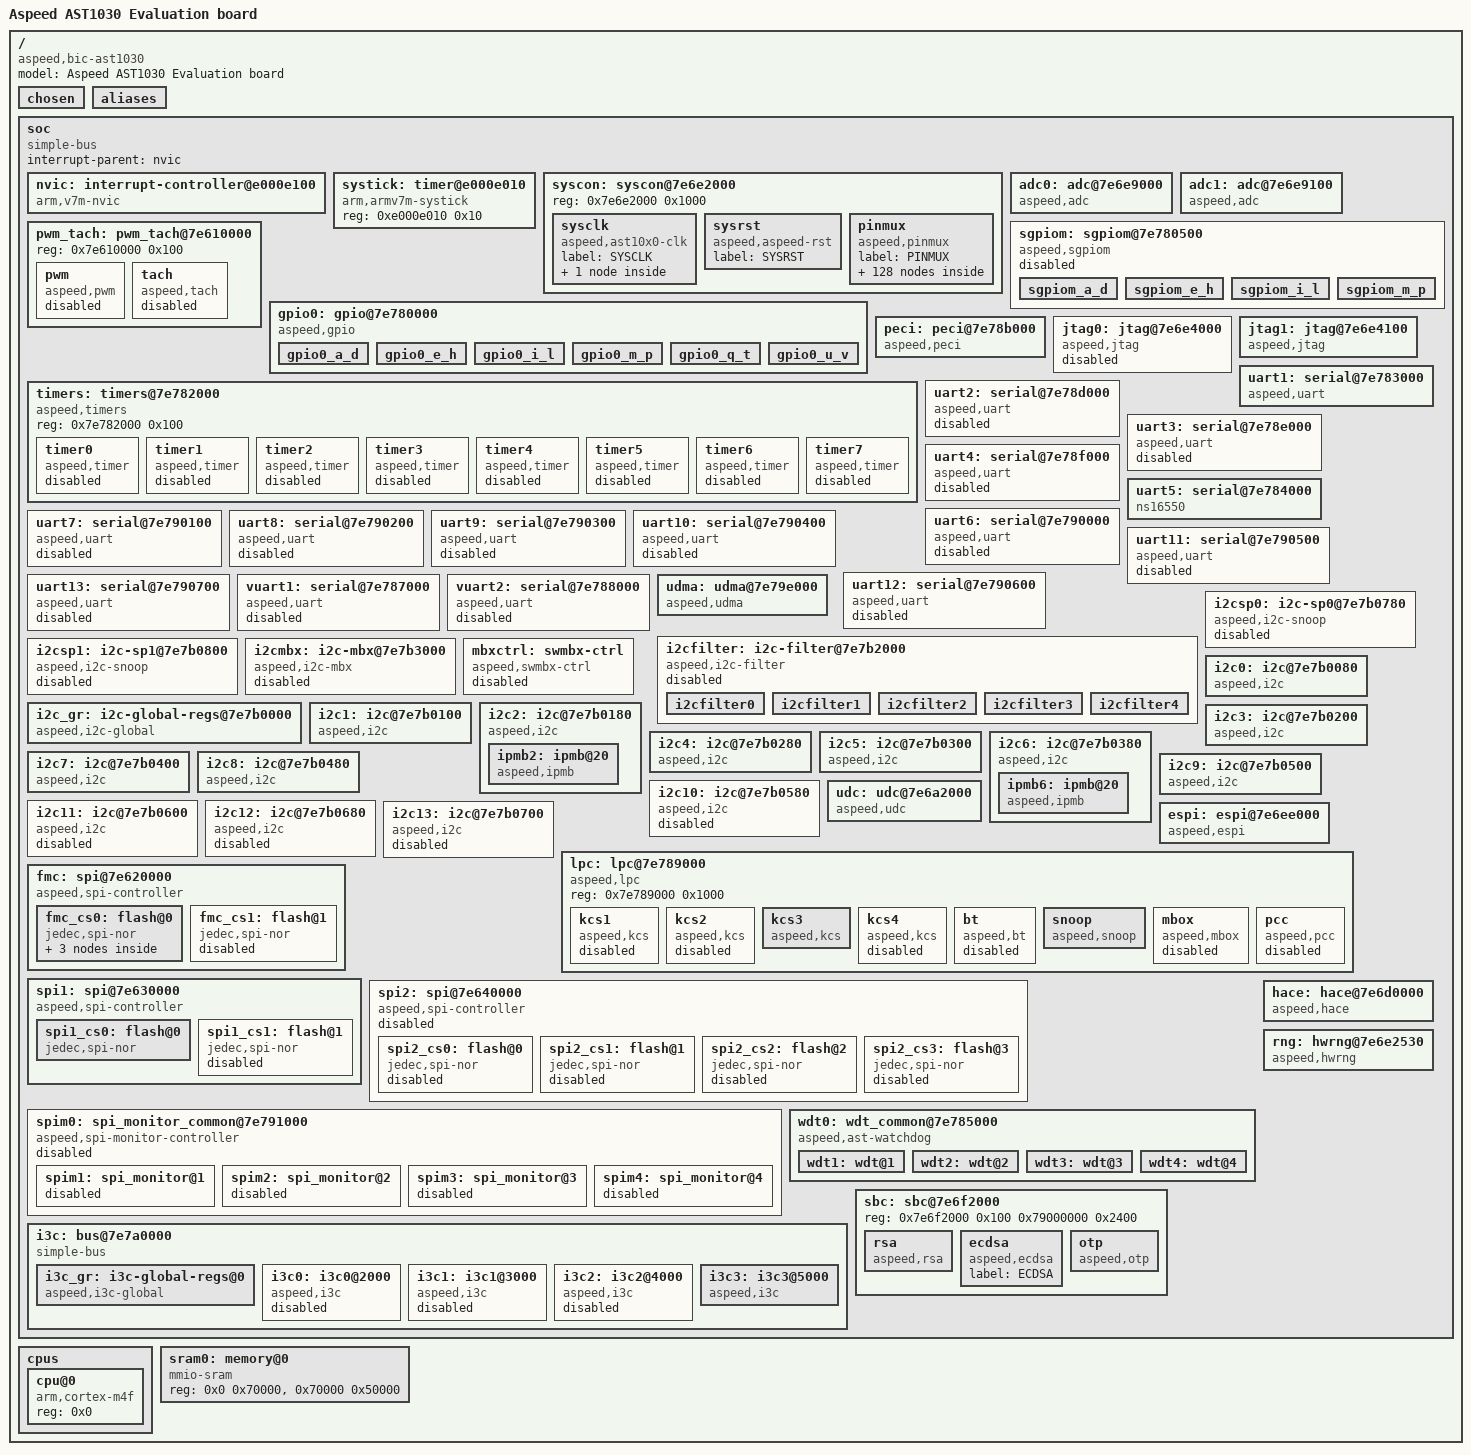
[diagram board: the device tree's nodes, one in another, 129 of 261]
/dts-v1/;

/ {
	#address-cells = < 0x1 >;
	#size-cells = < 0x1 >;
	model = "Aspeed AST1030 Evaluation board";
	compatible = "aspeed,bic-ast1030", "aspeed,ast1030";
	chosen {
		zephyr,console = &uart5;
		zephyr,shell-uart = &uart5;
		zephyr,sram = &sram0;
		zephyr,flash = &fmc_cs0;
		zephyr,entropy = &rng;
	};
	aliases {
	};
	soc {
		#address-cells = < 0x1 >;
		#size-cells = < 0x1 >;
		compatible = "simple-bus";
		interrupt-parent = < &nvic >;
		ranges;
		nvic: interrupt-controller@e000e100 {
			compatible = "arm,v7m-nvic";
			reg = < 0xe000e100 0xc00 >;
			interrupt-controller;
			#interrupt-cells = < 0x2 >;
			arm,num-irq-priority-bits = < 0x3 >;
			phandle = < 0x1 >;
		};
		systick: timer@e000e010 {
			compatible = "arm,armv7m-systick";
			reg = < 0xe000e010 0x10 >;
		};
		syscon: syscon@7e6e2000 {
			reg = < 0x7e6e2000 0x1000 >;
			phandle = < 0x5 >;
			sysclk: sysclk {
				compatible = "aspeed,ast10x0-clk";
				#clock-cells = < 0x1 >;
				label = "SYSCLK";
				phandle = < 0x2 >;
				adc_clk: adc_clk {
					#clock-cells = < 0x0 >;
					compatible = "fixed-factor-clock";
					clocks = < &sysclk 0x40 >;
					clock-mult = < 0x1 >;
					clock-div = < 0x2 >;
					label = "ADC_CLK";
					phandle = < 0x3 >;
				};
			};
			sysrst: sysrst {
				compatible = "aspeed,aspeed-rst";
				#reset-cells = < 0x1 >;
				label = "SYSRST";
				phandle = < 0x4 >;
			};
			pinmux: pinmux {
				compatible = "aspeed,pinmux";
				label = "PINMUX";
				pinctrl_adc0_default: adc0_default {
					phandle = < 0x6 >;
				};
				pinctrl_adc1_default: adc1_default {
					phandle = < 0x7 >;
				};
				pinctrl_adc2_default: adc2_default {
					phandle = < 0x8 >;
				};
				pinctrl_adc3_default: adc3_default {
					phandle = < 0x9 >;
				};
				pinctrl_adc4_default: adc4_default {
					phandle = < 0xa >;
				};
				pinctrl_adc5_default: adc5_default {
					phandle = < 0xb >;
				};
				pinctrl_adc6_default: adc6_default {
					phandle = < 0xc >;
				};
				pinctrl_adc7_default: adc7_default {
					phandle = < 0xd >;
				};
				pinctrl_adc8_default: adc8_default {
					phandle = < 0xe >;
				};
				pinctrl_adc9_default: adc9_default {
					phandle = < 0xf >;
				};
				pinctrl_adc10_default: adc10_default {
					phandle = < 0x10 >;
				};
				pinctrl_adc11_default: adc11_default {
					phandle = < 0x11 >;
				};
				pinctrl_adc12_default: adc12_default {
					phandle = < 0x12 >;
				};
				pinctrl_adc13_default: adc13_default {
					phandle = < 0x13 >;
				};
				pinctrl_adc14_default: adc14_default {
					phandle = < 0x14 >;
				};
				pinctrl_adc15_default: adc15_default {
					phandle = < 0x15 >;
				};
				pinctrl_i2c0_default: i2c0_default {
					phandle = < 0x25 >;
				};
				pinctrl_i2c1_default: i2c1_default {
					phandle = < 0x26 >;
				};
				pinctrl_i2c2_default: i2c2_default {
					phandle = < 0x27 >;
				};
				pinctrl_i2c3_default: i2c3_default {
					phandle = < 0x28 >;
				};
				pinctrl_i2c4_default: i2c4_default {
					phandle = < 0x29 >;
				};
				pinctrl_i2c5_default: i2c5_default {
					phandle = < 0x2a >;
				};
				pinctrl_i2c6_default: i2c6_default {
					phandle = < 0x2b >;
				};
				pinctrl_i2c7_default: i2c7_default {
					phandle = < 0x2c >;
				};
				pinctrl_i2c8_default: i2c8_default {
					phandle = < 0x2d >;
				};
				pinctrl_i2c9_default: i2c9_default {
					phandle = < 0x2e >;
				};
				pinctrl_i2c10_default: i2c10_default {
					phandle = < 0x2f >;
				};
				pinctrl_i2c11_default: i2c11_default {
					phandle = < 0x30 >;
				};
				pinctrl_i2c12_default: i2c12_default {
					phandle = < 0x31 >;
				};
				pinctrl_i2c13_default: i2c13_default {
					phandle = < 0x32 >;
				};
				pinctrl_arm_ice_default: arm_ice_default {
				};
				pinctrl_jtagm0_default: jtagm0_default {
					phandle = < 0x17 >;
				};
				pinctrl_jtagm1_default: jtagm1_default {
					phandle = < 0x18 >;
				};
				pinctrl_pwm0_default: pwm0_default {
				};
				pinctrl_pwm1_default: pwm1_default {
				};
				pinctrl_pwm2_default: pwm2_default {
				};
				pinctrl_pwm3_default: pwm3_default {
				};
				pinctrl_pwm4_default: pwm4_default {
				};
				pinctrl_pwm5_default: pwm5_default {
				};
				pinctrl_pwm6_default: pwm6_default {
				};
				pinctrl_pwm7_default: pwm7_default {
				};
				pinctrl_pwm8_default: pwm8_default {
				};
				pinctrl_pwm9_default: pwm9_default {
				};
				pinctrl_pwm10_default: pwm10_default {
				};
				pinctrl_pwm11_default: pwm11_default {
				};
				pinctrl_pwm12_default: pwm12_default {
				};
				pinctrl_pwm13_default: pwm13_default {
				};
				pinctrl_pwm14_default: pwm14_default {
				};
				pinctrl_pwm15_default: pwm15_default {
				};
				pinctrl_sgpiom_default: sgpiom_default {
					phandle = < 0x16 >;
				};
				pinctrl_tach0_default: tach0_default {
				};
				pinctrl_tach1_default: tach1_default {
				};
				pinctrl_tach2_default: tach2_default {
				};
				pinctrl_tach3_default: tach3_default {
				};
				pinctrl_tach4_default: tach4_default {
				};
				pinctrl_tach5_default: tach5_default {
				};
				pinctrl_tach6_default: tach6_default {
				};
				pinctrl_tach7_default: tach7_default {
				};
				pinctrl_tach8_default: tach8_default {
				};
				pinctrl_tach9_default: tach9_default {
				};
				pinctrl_tach10_default: tach10_default {
				};
				pinctrl_tach11_default: tach11_default {
				};
				pinctrl_tach12_default: tach12_default {
				};
				pinctrl_tach13_default: tach13_default {
				};
				pinctrl_tach14_default: tach14_default {
				};
				pinctrl_tach15_default: tach15_default {
				};
				pinctrl_uart1_default: uart1_default {
					phandle = < 0x19 >;
				};
				pinctrl_uart2_default: uart2_default {
					phandle = < 0x1a >;
				};
				pinctrl_uart3_default: uart3_default {
					phandle = < 0x1b >;
				};
				pinctrl_uart4_default: uart4_default {
					phandle = < 0x1c >;
				};
				pinctrl_uart6_default: uart6_default {
					phandle = < 0x1d >;
				};
				pinctrl_uart7_default: uart7_default {
					phandle = < 0x1e >;
				};
				pinctrl_uart8_default: uart8_default {
					phandle = < 0x1f >;
				};
				pinctrl_uart9_default: uart9_default {
					phandle = < 0x20 >;
				};
				pinctrl_uart10_default: uart10_default {
					phandle = < 0x21 >;
				};
				pinctrl_uart11_default: uart11_default {
					phandle = < 0x22 >;
				};
				pinctrl_uart12_default: uart12_default {
					phandle = < 0x23 >;
				};
				pinctrl_uart13_default: uart13_default {
					phandle = < 0x24 >;
				};
				pinctrl_i3c0_default: i3c0_default {
				};
				pinctrl_i3c1_default: i3c1_default {
				};
				pinctrl_i3c2_default: i3c2_default {
				};
				pinctrl_i3c3_default: i3c3_default {
					phandle = < 0x3a >;
				};
				pinctrl_hvi3c0_default: hvi3c0_default {
					phandle = < 0x38 >;
				};
				pinctrl_hvi3c1_default: hvi3c1_default {
					phandle = < 0x39 >;
				};
				pinctrl_hvi3c2_default: hvi3c2_default {
				};
				pinctrl_hvi3c3_default: hvi3c3_default {
				};
				pinctrl_fmc_quad: fmc_quad {
					phandle = < 0x33 >;
				};
				pinctrl_spi1_quad: spi1_quad {
					phandle = < 0x34 >;
				};
				pinctrl_spi2_default: spi2_default {
					phandle = < 0x35 >;
				};
				pinctrl_spi2_cs1: spi2_cs1 {
					phandle = < 0x36 >;
				};
				pinctrl_spi2_quad: spi2_quad {
					phandle = < 0x37 >;
				};
				pinctrl_spim1_cs: spim1_cs {
				};
				pinctrl_spim1_in_default: spim1_in_default {
				};
				pinctrl_spim1_out_default: spim1_out_default {
				};
				pinctrl_spim1_qspi_in_default: spim1_qspi_in_default {
				};
				pinctrl_spim1_qspi_out_default: spim1_qspi_out_default {
				};
				pinctrl_spim1_rst_in: spim1_rst_in {
				};
				pinctrl_spim1_rst_out: spim1_rst_out {
				};
				pinctrl_spim1_muxsel: spim1_muxsel {
				};
				pinctrl_spim2_cs: spim2_cs {
				};
				pinctrl_spim2_in_default: spim2_in_default {
				};
				pinctrl_spim2_out_default: spim2_out_default {
				};
				pinctrl_spim2_qspi_in_default: spim2_qspi_in_default {
				};
				pinctrl_spim2_qspi_out_default: spim2_qspi_out_default {
				};
				pinctrl_spim2_rst_in: spim2_rst_in {
				};
				pinctrl_spim2_rst_out: spim2_rst_out {
				};
				pinctrl_spim2_muxsel: spim2_muxsel {
				};
				pinctrl_spim3_cs: spim3_cs {
				};
				pinctrl_spim3_in_default: spim3_in_default {
				};
				pinctrl_spim3_out_default: spim3_out_default {
				};
				pinctrl_spim3_qspi_in_default: spim3_qspi_in_default {
				};
				pinctrl_spim3_qspi_out_default: spim3_qspi_out_default {
				};
				pinctrl_spim3_rst_in: spim3_rst_in {
				};
				pinctrl_spim3_rst_out: spim3_rst_out {
				};
				pinctrl_spim3_muxsel: spim3_muxsel {
				};
				pinctrl_spim4_cs: spim4_cs {
				};
				pinctrl_spim4_in_default: spim4_in_default {
				};
				pinctrl_spim4_out_default: spim4_out_default {
				};
				pinctrl_spim4_qspi_in_default: spim4_qspi_in_default {
				};
				pinctrl_spim4_qspi_out_default: spim4_qspi_out_default {
				};
				pinctrl_spim4_rst_in: spim4_rst_in {
				};
				pinctrl_spim4_rst_out: spim4_rst_out {
				};
				pinctrl_spim4_muxsel: spim4_muxsel {
				};
				pinctrl_smbflt_default: smbflt_default {
				};
				pinctrl_passthrough0_default: passthrough0_default {
				};
				pinctrl_passthrough1_default: passthrough1_default {
				};
				pinctrl_passthrough2_default: passthrough2_default {
				};
				pinctrl_passthrough3_default: passthrough3_default {
				};
			};
		};
		adc0: adc@7e6e9000 {
			compatible = "aspeed,adc";
			reg = < 0x7e6e9000 0x100 >;
			clocks = < &adc_clk >;
			resets = < &sysrst 0x505417 >;
			interrupts = < 0x2e 0x1 >;
			#io-channel-cells = < 0x1 >;
			aspeed,scu = < &syscon >;
			aspeed,trim-data-locate = < 0x5bc 0x3c000 >;
			label = "ADC0";
			status = "okay";
			pinctrl-0 = < &pinctrl_adc0_default &pinctrl_adc1_default &pinctrl_adc2_default &pinctrl_adc3_default &pinctrl_adc4_default &pinctrl_adc5_default &pinctrl_adc6_default &pinctrl_adc7_default >;
		};
		adc1: adc@7e6e9100 {
			compatible = "aspeed,adc";
			reg = < 0x7e6e9100 0x100 >;
			clocks = < &adc_clk >;
			resets = < &sysrst 0x505417 >;
			interrupts = < 0x2e 0x1 >;
			#io-channel-cells = < 0x1 >;
			aspeed,scu = < &syscon >;
			aspeed,trim-data-locate = < 0x5d0 0xf00 >;
			label = "ADC1";
			status = "okay";
			pinctrl-0 = < &pinctrl_adc8_default &pinctrl_adc9_default &pinctrl_adc10_default &pinctrl_adc11_default &pinctrl_adc12_default &pinctrl_adc13_default &pinctrl_adc14_default &pinctrl_adc15_default >;
		};
		pwm_tach: pwm_tach@7e610000 {
			reg = < 0x7e610000 0x100 >;
			pwm: pwm {
				compatible = "aspeed,pwm";
				#pwm-cells = < 0x3 >;
				npwms = < 0x10 >;
				clocks = < &sysclk 0x41 >;
				resets = < &sysrst 0x505405 >;
				label = "PWM";
				status = "disabled";
			};
			tach: tach {
				compatible = "aspeed,tach";
				#address-cells = < 0x1 >;
				#size-cells = < 0x0 >;
				clocks = < &sysclk 0x41 >;
				resets = < &sysrst 0x505405 >;
				interrupts = < 0x2c 0x1 >;
				label = "TACH";
				status = "disabled";
			};
		};
		gpio0: gpio@7e780000 {
			compatible = "aspeed,gpio";
			reg = < 0x7e780000 0x400 >;
			interrupts = < 0xb 0x1 >;
			clocks = < &sysclk 0x40 >;
			gpio0_a_d: gpio0_a_d {
				#gpio-cells = < 0x2 >;
				gpio-controller;
				ngpios = < 0x20 >;
				interrupt-controller;
				#interrupt-cells = < 0x2 >;
				gpio-reserved = < 0x0 >;
				label = "GPIO0_A_D";
				pin-offset = < 0x0 >;
				aspeed,persist-maps = < 0x8000000 >;
			};
			gpio0_e_h: gpio0_e_h {
				#gpio-cells = < 0x2 >;
				gpio-controller;
				ngpios = < 0x20 >;
				interrupt-controller;
				#interrupt-cells = < 0x2 >;
				gpio-reserved = < 0x0 >;
				label = "GPIO0_E_H";
				pin-offset = < 0x20 >;
			};
			gpio0_i_l: gpio0_i_l {
				#gpio-cells = < 0x2 >;
				gpio-controller;
				ngpios = < 0x20 >;
				interrupt-controller;
				#interrupt-cells = < 0x2 >;
				gpio-reserved = < 0x0 >;
				label = "GPIO0_I_L";
				pin-offset = < 0x40 >;
			};
			gpio0_m_p: gpio0_m_p {
				#gpio-cells = < 0x2 >;
				gpio-controller;
				ngpios = < 0x20 >;
				interrupt-controller;
				#interrupt-cells = < 0x2 >;
				gpio-reserved = < 0xc0 >;
				label = "GPIO0_M_P";
				pin-offset = < 0x60 >;
			};
			gpio0_q_t: gpio0_q_t {
				#gpio-cells = < 0x2 >;
				gpio-controller;
				ngpios = < 0x20 >;
				gpio-reserved = < 0xf9f3e0 >;
				interrupt-controller;
				#interrupt-cells = < 0x2 >;
				label = "GPIO0_Q_T";
				pin-offset = < 0x80 >;
			};
			gpio0_u_v: gpio0_u_v {
				#gpio-cells = < 0x2 >;
				gpio-controller;
				ngpios = < 0x8 >;
				interrupt-controller;
				#interrupt-cells = < 0x2 >;
				gpio-reserved = < 0x0 >;
				label = "GPIO0_U_V";
				pin-offset = < 0xa0 >;
			};
		};
		sgpiom: sgpiom@7e780500 {
			compatible = "aspeed,sgpiom";
			reg = < 0x7e780500 0x100 >;
			interrupts = < 0x33 0x1 >;
			clocks = < &sysclk 0x40 >;
			pinctrl-0 = < &pinctrl_sgpiom_default >;
			ngpios = < 0x80 >;
			status = "disabled";
			sgpiom_a_d: sgpiom_a_d {
				#gpio-cells = < 0x2 >;
				gpio-controller;
				ngpios = < 0x20 >;
				interrupt-controller;
				#interrupt-cells = < 0x2 >;
				label = "SGPIOM_A_D";
				pin-offset = < 0x0 >;
			};
			sgpiom_e_h: sgpiom_e_h {
				#gpio-cells = < 0x2 >;
				gpio-controller;
				ngpios = < 0x20 >;
				interrupt-controller;
				#interrupt-cells = < 0x2 >;
				label = "SGPIOM_E_H";
				pin-offset = < 0x20 >;
			};
			sgpiom_i_l: sgpiom_i_l {
				#gpio-cells = < 0x2 >;
				gpio-controller;
				ngpios = < 0x20 >;
				interrupt-controller;
				#interrupt-cells = < 0x2 >;
				label = "SGPIOM_I_L";
				pin-offset = < 0x40 >;
			};
			sgpiom_m_p: sgpiom_m_p {
				#gpio-cells = < 0x2 >;
				gpio-controller;
				ngpios = < 0x20 >;
				interrupt-controller;
				#interrupt-cells = < 0x2 >;
				label = "SGPIOM_M_P";
				pin-offset = < 0x60 >;
			};
		};
		peci: peci@7e78b000 {
			compatible = "aspeed,peci";
			reg = < 0x7e78b000 0x100 >;
			interrupts = < 0x26 0x1 >;
			clocks = < &sysclk 0x41 >;
			resets = < &sysrst 0x505404 >;
			label = "PECI";
			#address-cells = < 0x1 >;
			#size-cells = < 0x0 >;
		};
		jtag0: jtag@7e6e4000 {
			compatible = "aspeed,jtag";
			reg = < 0x7e6e4000 0x20 >;
			interrupts = < 0x1b 0x1 >;
			clocks = < &sysclk 0x41 >;
			resets = < &sysrst 0x50541a >;
			label = "JTAG0";
			pinctrl-0 = < &pinctrl_jtagm0_default >;
			status = "disabled";
		};
		jtag1: jtag@7e6e4100 {
			compatible = "aspeed,jtag";
			reg = < 0x7e6e4100 0x20 >;
			interrupts = < 0x35 0x1 >;
			clocks = < &sysclk 0x41 >;
			resets = < &sysrst 0x505416 >;
			label = "JTAG1";
			pinctrl-0 = < &pinctrl_jtagm1_default >;
			status = "okay";
		};
		timers: timers@7e782000 {
			compatible = "aspeed,timers";
			reg = < 0x7e782000 0x100 >;
			timer0: timer0 {
				compatible = "aspeed,timer";
				interrupts = < 0x10 0x1 >;
				clocks = < &sysclk 0x40 >;
				label = "TIMER0";
				index = < 0x0 >;
				status = "disabled";
			};
			timer1: timer1 {
				compatible = "aspeed,timer";
				interrupts = < 0x11 0x1 >;
				clocks = < &sysclk 0x40 >;
				label = "TIMER1";
				index = < 0x1 >;
				status = "disabled";
			};
			timer2: timer2 {
				compatible = "aspeed,timer";
				interrupts = < 0x12 0x1 >;
				clocks = < &sysclk 0x40 >;
				label = "TIMER2";
				index = < 0x2 >;
				status = "disabled";
			};
			timer3: timer3 {
				compatible = "aspeed,timer";
				interrupts = < 0x13 0x1 >;
				clocks = < &sysclk 0x40 >;
				label = "TIMER3";
				index = < 0x3 >;
				status = "disabled";
			};
			timer4: timer4 {
				compatible = "aspeed,timer";
				interrupts = < 0x14 0x1 >;
				clocks = < &sysclk 0x40 >;
				label = "TIMER4";
				index = < 0x4 >;
				status = "disabled";
			};
			timer5: timer5 {
				compatible = "aspeed,timer";
				interrupts = < 0x15 0x1 >;
				clocks = < &sysclk 0x40 >;
				label = "TIMER5";
				index = < 0x5 >;
				status = "disabled";
			};
			timer6: timer6 {
				compatible = "aspeed,timer";
				interrupts = < 0x16 0x1 >;
				clocks = < &sysclk 0x40 >;
				label = "TIMER6";
				index = < 0x6 >;
				status = "disabled";
			};
			timer7: timer7 {
				compatible = "aspeed,timer";
				interrupts = < 0x17 0x1 >;
				clocks = < &sysclk 0x40 >;
				label = "TIMER7";
				index = < 0x7 >;
				status = "disabled";
			};
		};
		uart1: serial@7e783000 {
			compatible = "aspeed,uart";
			reg = < 0x7e783000 0x1000 >;
			interrupts = < 0x2f 0x1 >;
			clocks = < &sysclk 0x30 >;
			status = "okay";
			pinctrl-0 = < &pinctrl_uart1_default >;
			label = "UART_1";
		};
		uart2: serial@7e78d000 {
			compatible = "aspeed,uart";
			reg = < 0x7e78d000 0x100 >;
			interrupts = < 0x30 0x1 >;
			clocks = < &sysclk 0x31 >;
			status = "disabled";
			pinctrl-0 = < &pinctrl_uart2_default >;
			label = "UART_2";
		};
		uart3: serial@7e78e000 {
			compatible = "aspeed,uart";
			reg = < 0x7e78e000 0x100 >;
			interrupts = < 0x31 0x1 >;
			clocks = < &sysclk 0x32 >;
			status = "disabled";
			pinctrl-0 = < &pinctrl_uart3_default >;
			label = "UART_3";
		};
		uart4: serial@7e78f000 {
			compatible = "aspeed,uart";
			reg = < 0x7e78f000 0x100 >;
			interrupts = < 0x32 0x1 >;
			clocks = < &sysclk 0x33 >;
			status = "disabled";
			pinctrl-0 = < &pinctrl_uart4_default >;
			label = "UART_4";
		};
		uart5: serial@7e784000 {
			compatible = "ns16550";
			reg = < 0x7e784000 0x1000 >;
			interrupts = < 0x8 0x1 >;
			clocks = < &sysclk 0x42 >;
			status = "okay";
			label = "UART_5";
			clock-frequency = < 0x1c2b89 >;
			current-speed = < 0xe100 >;
		};
		uart6: serial@7e790000 {
			compatible = "aspeed,uart";
			reg = < 0x7e790000 0x100 >;
			interrupts = < 0x39 0x1 >;
			clocks = < &sysclk 0x36 >;
			status = "disabled";
			pinctrl-0 = < &pinctrl_uart6_default >;
			label = "UART_6";
		};
		uart7: serial@7e790100 {
			compatible = "aspeed,uart";
			reg = < 0x7e790100 0x100 >;
			interrupts = < 0x3a 0x1 >;
			clocks = < &sysclk 0x37 >;
			status = "disabled";
			pinctrl-0 = < &pinctrl_uart7_default >;
			label = "UART_7";
		};
		uart8: serial@7e790200 {
			compatible = "aspeed,uart";
			reg = < 0x7e790200 0x100 >;
			interrupts = < 0x3b 0x1 >;
			clocks = < &sysclk 0x38 >;
			status = "disabled";
			pinctrl-0 = < &pinctrl_uart8_default >;
			label = "UART_8";
		};
		uart9: serial@7e790300 {
			compatible = "aspeed,uart";
			reg = < 0x7e790300 0x100 >;
			interrupts = < 0x3c 0x1 >;
			clocks = < &sysclk 0x39 >;
			status = "disabled";
			pinctrl-0 = < &pinctrl_uart9_default >;
			label = "UART_9";
		};
		uart10: serial@7e790400 {
			compatible = "aspeed,uart";
			reg = < 0x7e790400 0x100 >;
			interrupts = < 0x3d 0x1 >;
			clocks = < &sysclk 0x3a >;
			status = "disabled";
			pinctrl-0 = < &pinctrl_uart10_default >;
			label = "UART_10";
		};
		uart11: serial@7e790500 {
			compatible = "aspeed,uart";
			reg = < 0x7e790500 0x100 >;
			interrupts = < 0x3e 0x1 >;
			clocks = < &sysclk 0x3b >;
			status = "disabled";
			pinctrl-0 = < &pinctrl_uart11_default >;
			label = "UART_11";
		};
		uart12: serial@7e790600 {
			compatible = "aspeed,uart";
			reg = < 0x7e790600 0x100 >;
			interrupts = < 0x3f 0x1 >;
			clocks = < &sysclk 0x3c >;
			status = "disabled";
			pinctrl-0 = < &pinctrl_uart12_default >;
			label = "UART_12";
		};
		uart13: serial@7e790700 {
			compatible = "aspeed,uart";
			reg = < 0x7e790700 0x100 >;
			interrupts = < 0x40 0x1 >;
			clocks = < &sysclk 0x3d >;
			status = "disabled";
			pinctrl-0 = < &pinctrl_uart13_default >;
			label = "UART_13";
		};
		vuart1: serial@7e787000 {
			compatible = "aspeed,uart";
			reg = < 0x7e787000 0x100 >;
			interrupts = < 0x93 0x1 >;
			clocks = < &sysclk 0x40 >;
			virtual = < 0x1 >;
			status = "disabled";
			label = "VUART_1";
		};
		vuart2: serial@7e788000 {
			compatible = "aspeed,uart";
			reg = < 0x7e788000 0x100 >;
			interrupts = < 0x94 0x1 >;
			clocks = < &sysclk 0x40 >;
			virtual = < 0x1 >;
			status = "disabled";
			label = "VUART_2";
		};
		udma: udma@7e79e000 {
			compatible = "aspeed,udma";
			interrupts = < 0x38 0x1 >;
			reg = < 0x7e79e000 0x1000 >;
		};
		i2cfilter: i2c-filter@7e7b2000 {
			compatible = "aspeed,i2c-filter";
			reg = < 0x7e7b2000 0x200 >;
			clocks = < &sysclk 0x40 >;
			interrupts = < 0x7f 0x1 >;
			status = "disabled";
			i2cfilter0: i2cfilter0 {
				index = < 0x0 >;
				clock = < 0x64 >;
				label = "I2C_FILTER_0";
			};
			i2cfilter1: i2cfilter1 {
				index = < 0x1 >;
				clock = < 0x64 >;
				label = "I2C_FILTER_1";
			};
			i2cfilter2: i2cfilter2 {
				index = < 0x2 >;
				clock = < 0x64 >;
				label = "I2C_FILTER_2";
			};
			i2cfilter3: i2cfilter3 {
				index = < 0x3 >;
				clock = < 0x64 >;
				label = "I2C_FILTER_3";
			};
			i2cfilter4: i2cfilter4 {
				index = < 0x4 >;
				clock = < 0x64 >;
				label = "I2C_FILTER_4";
			};
		};
		i2csp0: i2c-sp0@7e7b0780 {
			compatible = "aspeed,i2c-snoop";
			#address-cells = < 0x1 >;
			#size-cells = < 0x0 >;
			reg = < 0x7e7b0780 0x80 >;
			label = "I2C_SP_0";
			status = "disabled";
		};
		i2csp1: i2c-sp1@7e7b0800 {
			compatible = "aspeed,i2c-snoop";
			#address-cells = < 0x1 >;
			#size-cells = < 0x0 >;
			reg = < 0x7e7b0800 0x80 >;
			label = "I2C_SP_1";
			status = "disabled";
		};
		i2cmbx: i2c-mbx@7e7b3000 {
			compatible = "aspeed,i2c-mbx";
			#address-cells = < 0x1 >;
			#size-cells = < 0x0 >;
			reg = < 0x7e7b3000 0x100 >;
			interrupts = < 0x80 0x1 >;
			label = "I2C_MBX";
			status = "disabled";
		};
		mbxctrl: swmbx-ctrl {
			compatible = "aspeed,swmbx-ctrl";
			size = < 0x100 >;
			label = "SWMBX";
			status = "disabled";
		};
		i2c_gr: i2c-global-regs@7e7b0000 {
			compatible = "aspeed,i2c-global";
			#address-cells = < 0x1 >;
			#size-cells = < 0x0 >;
			reg = < 0x7e7b0000 0x20 >;
			clocks = < &sysclk 0x40 >;
			resets = < &sysrst 0x505402 >;
			clk-divider = < 0x62220803 >;
			label = "I2C_GLOBAL";
		};
		i2c0: i2c@7e7b0080 {
			compatible = "aspeed,i2c";
			clock-frequency = < 0x186a0 >;
			#address-cells = < 0x1 >;
			#size-cells = < 0x0 >;
			reg = < 0x7e7b0080 0x80 >;
			interrupts = < 0x6e 0x1 >;
			clocks = < &sysclk 0x40 >;
			xfer-mode = "DMA";
			multi-master = < 0x1 >;
			smbus-timeout = < 0x1 >;
			manual-high-count = < 0x0 >;
			manual-low-count = < 0x0 >;
			manual-sda-delay = < 0x0 >;
			pinctrl-0 = < &pinctrl_i2c0_default >;
			status = "okay";
			label = "I2C_0";
		};
		i2c1: i2c@7e7b0100 {
			compatible = "aspeed,i2c";
			clock-frequency = < 0x186a0 >;
			#address-cells = < 0x1 >;
			#size-cells = < 0x0 >;
			reg = < 0x7e7b0100 0x80 >;
			interrupts = < 0x6f 0x1 >;
			clocks = < &sysclk 0x40 >;
			xfer-mode = "DMA";
			multi-master = < 0x1 >;
			smbus-timeout = < 0x1 >;
			manual-high-count = < 0x0 >;
			manual-low-count = < 0x0 >;
			manual-sda-delay = < 0x0 >;
			pinctrl-0 = < &pinctrl_i2c1_default >;
			status = "okay";
			label = "I2C_1";
		};
		i2c2: i2c@7e7b0180 {
			compatible = "aspeed,i2c";
			clock-frequency = < 0xf4240 >;
			#address-cells = < 0x1 >;
			#size-cells = < 0x0 >;
			reg = < 0x7e7b0180 0x80 >;
			interrupts = < 0x70 0x1 >;
			clocks = < &sysclk 0x40 >;
			xfer-mode = "DMA";
			multi-master = < 0x1 >;
			smbus-timeout = < 0x1 >;
			manual-high-count = < 0x0 >;
			manual-low-count = < 0x0 >;
			manual-sda-delay = < 0x0 >;
			pinctrl-0 = < &pinctrl_i2c2_default >;
			status = "okay";
			label = "I2C_2";
			ipmb2: ipmb@20 {
				compatible = "aspeed,ipmb";
				reg = < 0x20 >;
				label = "IPMB_2";
				size = < 0xa >;
			};
		};
		i2c3: i2c@7e7b0200 {
			compatible = "aspeed,i2c";
			clock-frequency = < 0x186a0 >;
			#address-cells = < 0x1 >;
			#size-cells = < 0x0 >;
			reg = < 0x7e7b0200 0x80 >;
			interrupts = < 0x71 0x1 >;
			clocks = < &sysclk 0x40 >;
			xfer-mode = "DMA";
			multi-master = < 0x1 >;
			smbus-timeout = < 0x1 >;
			manual-high-count = < 0x0 >;
			manual-low-count = < 0x0 >;
			manual-sda-delay = < 0x0 >;
			pinctrl-0 = < &pinctrl_i2c3_default >;
			status = "okay";
			label = "I2C_3";
		};
		i2c4: i2c@7e7b0280 {
			compatible = "aspeed,i2c";
			clock-frequency = < 0x186a0 >;
			#address-cells = < 0x1 >;
			#size-cells = < 0x0 >;
			reg = < 0x7e7b0280 0x80 >;
			interrupts = < 0x72 0x1 >;
			clocks = < &sysclk 0x40 >;
			xfer-mode = "DMA";
			multi-master = < 0x1 >;
			smbus-timeout = < 0x1 >;
			manual-high-count = < 0x0 >;
			manual-low-count = < 0x0 >;
			manual-sda-delay = < 0x0 >;
			pinctrl-0 = < &pinctrl_i2c4_default >;
			status = "okay";
			label = "I2C_4";
		};
		i2c5: i2c@7e7b0300 {
			compatible = "aspeed,i2c";
			clock-frequency = < 0x61a80 >;
			#address-cells = < 0x1 >;
			#size-cells = < 0x0 >;
			reg = < 0x7e7b0300 0x80 >;
			interrupts = < 0x73 0x1 >;
			clocks = < &sysclk 0x40 >;
			xfer-mode = "DMA";
			multi-master = < 0x1 >;
			smbus-timeout = < 0x1 >;
			manual-high-count = < 0x0 >;
			manual-low-count = < 0x0 >;
			manual-sda-delay = < 0x0 >;
			pinctrl-0 = < &pinctrl_i2c5_default >;
			status = "okay";
			label = "I2C_5";
		};
		i2c6: i2c@7e7b0380 {
			compatible = "aspeed,i2c";
			clock-frequency = < 0xf4240 >;
			#address-cells = < 0x1 >;
			#size-cells = < 0x0 >;
			reg = < 0x7e7b0380 0x80 >;
			interrupts = < 0x74 0x1 >;
			clocks = < &sysclk 0x40 >;
			xfer-mode = "DMA";
			multi-master = < 0x1 >;
			smbus-timeout = < 0x1 >;
			manual-high-count = < 0x0 >;
			manual-low-count = < 0x0 >;
			manual-sda-delay = < 0x0 >;
			pinctrl-0 = < &pinctrl_i2c6_default >;
			status = "okay";
			label = "I2C_6";
			ipmb6: ipmb@20 {
				compatible = "aspeed,ipmb";
				reg = < 0x20 >;
				label = "IPMB_6";
				size = < 0xa >;
				status = "okay";
			};
		};
		i2c7: i2c@7e7b0400 {
			compatible = "aspeed,i2c";
			clock-frequency = < 0x61a80 >;
			#address-cells = < 0x1 >;
			#size-cells = < 0x0 >;
			reg = < 0x7e7b0400 0x80 >;
			interrupts = < 0x75 0x1 >;
			clocks = < &sysclk 0x40 >;
			xfer-mode = "DMA";
			multi-master = < 0x1 >;
			smbus-timeout = < 0x1 >;
			manual-high-count = < 0x0 >;
			manual-low-count = < 0x0 >;
			manual-sda-delay = < 0x0 >;
			pinctrl-0 = < &pinctrl_i2c7_default >;
			status = "okay";
			label = "I2C_7";
		};
		i2c8: i2c@7e7b0480 {
			compatible = "aspeed,i2c";
			clock-frequency = < 0x61a80 >;
			#address-cells = < 0x1 >;
			#size-cells = < 0x0 >;
			reg = < 0x7e7b0480 0x80 >;
			interrupts = < 0x76 0x1 >;
			clocks = < &sysclk 0x40 >;
			xfer-mode = "DMA";
			multi-master = < 0x1 >;
			smbus-timeout = < 0x1 >;
			manual-high-count = < 0x0 >;
			manual-low-count = < 0x0 >;
			manual-sda-delay = < 0x0 >;
			pinctrl-0 = < &pinctrl_i2c8_default >;
			status = "okay";
			label = "I2C_8";
		};
		i2c9: i2c@7e7b0500 {
			compatible = "aspeed,i2c";
			clock-frequency = < 0x61a80 >;
			#address-cells = < 0x1 >;
			#size-cells = < 0x0 >;
			reg = < 0x7e7b0500 0x80 >;
			interrupts = < 0x77 0x1 >;
			clocks = < &sysclk 0x40 >;
			xfer-mode = "DMA";
			multi-master = < 0x1 >;
			smbus-timeout = < 0x1 >;
			manual-high-count = < 0x0 >;
			manual-low-count = < 0x0 >;
			manual-sda-delay = < 0x0 >;
			pinctrl-0 = < &pinctrl_i2c9_default >;
			status = "okay";
			label = "I2C_9";
		};
		i2c10: i2c@7e7b0580 {
			compatible = "aspeed,i2c";
			clock-frequency = < 0x61a80 >;
			#address-cells = < 0x1 >;
			#size-cells = < 0x0 >;
			reg = < 0x7e7b0580 0x80 >;
			interrupts = < 0x78 0x1 >;
			clocks = < &sysclk 0x40 >;
			xfer-mode = "DMA";
			multi-master = < 0x1 >;
			smbus-timeout = < 0x1 >;
			manual-high-count = < 0x0 >;
			manual-low-count = < 0x0 >;
			manual-sda-delay = < 0x0 >;
			pinctrl-0 = < &pinctrl_i2c10_default >;
			status = "disabled";
			label = "I2C_10";
		};
		i2c11: i2c@7e7b0600 {
			compatible = "aspeed,i2c";
			clock-frequency = < 0x61a80 >;
			#address-cells = < 0x1 >;
			#size-cells = < 0x0 >;
			reg = < 0x7e7b0600 0x80 >;
			interrupts = < 0x79 0x1 >;
			clocks = < &sysclk 0x40 >;
			xfer-mode = "DMA";
			multi-master = < 0x1 >;
			smbus-timeout = < 0x1 >;
			manual-high-count = < 0x0 >;
			manual-low-count = < 0x0 >;
			manual-sda-delay = < 0x0 >;
			pinctrl-0 = < &pinctrl_i2c11_default >;
			status = "disabled";
			label = "I2C_11";
		};
		i2c12: i2c@7e7b0680 {
			compatible = "aspeed,i2c";
			clock-frequency = < 0x61a80 >;
			#address-cells = < 0x1 >;
			#size-cells = < 0x0 >;
			reg = < 0x7e7b0680 0x80 >;
			interrupts = < 0x7a 0x1 >;
			clocks = < &sysclk 0x40 >;
			xfer-mode = "DMA";
			multi-master = < 0x1 >;
			smbus-timeout = < 0x1 >;
			manual-high-count = < 0x0 >;
			manual-low-count = < 0x0 >;
			manual-sda-delay = < 0x0 >;
			pinctrl-0 = < &pinctrl_i2c12_default >;
			status = "disabled";
			label = "I2C_12";
		};
		i2c13: i2c@7e7b0700 {
			compatible = "aspeed,i2c";
			clock-frequency = < 0x61a80 >;
			#address-cells = < 0x1 >;
			#size-cells = < 0x0 >;
			reg = < 0x7e7b0700 0x80 >;
			interrupts = < 0x7b 0x1 >;
			clocks = < &sysclk 0x40 >;
			xfer-mode = "DMA";
			multi-master = < 0x1 >;
			smbus-timeout = < 0x1 >;
			manual-high-count = < 0x0 >;
			manual-low-count = < 0x0 >;
			manual-sda-delay = < 0x0 >;
			pinctrl-0 = < &pinctrl_i2c13_default >;
			status = "disabled";
			label = "I2C_13";
		};
		espi: espi@7e6ee000 {
			compatible = "aspeed,espi";
			reg = < 0x7e6ee000 0x800 >;
			interrupts = < 0x2a 0x1 >;
			aspeed,scu = < &syscon >;
			status = "okay";
			label = "ESPI";
			perif,dma-mode;
			perif,memcyc-src-addr = < 0x98000000 >;
			perif,memcyc-size = < 0x10000 >;
			oob,dma-mode;
			flash,dma-mode;
			flash,safs-mode = < 0x2 >;
		};
		udc: udc@7e6a2000 {
			compatible = "aspeed,udc";
			reg = < 0x7e6a2000 0x1000 >;
			interrupts = < 0x9 0x1 >;
			num-bidir-endpoints = < 0x5 >;
			resets = < &sysrst 0x404403 >;
			label = "UDC";
			status = "okay";
		};
		lpc: lpc@7e789000 {
			compatible = "aspeed,lpc";
			reg = < 0x7e789000 0x1000 >;
			kcs1: kcs1 {
				compatible = "aspeed,kcs";
				interrupts = < 0x8a 0x1 >;
				chan = < 0x1 >;
				label = "KCS1";
				status = "disabled";
			};
			kcs2: kcs2 {
				compatible = "aspeed,kcs";
				interrupts = < 0x8b 0x1 >;
				chan = < 0x2 >;
				label = "KCS2";
				status = "disabled";
			};
			kcs3: kcs3 {
				compatible = "aspeed,kcs";
				interrupts = < 0x8c 0x1 >;
				chan = < 0x3 >;
				label = "KCS3";
				status = "okay";
				addr = < 0xca2 >;
			};
			kcs4: kcs4 {
				compatible = "aspeed,kcs";
				interrupts = < 0x8d 0x1 >;
				chan = < 0x4 >;
				label = "KCS4";
				status = "disabled";
			};
			bt: bt {
				compatible = "aspeed,bt";
				interrupts = < 0x8f 0x1 >;
				label = "BT";
				status = "disabled";
			};
			snoop: snoop {
				compatible = "aspeed,snoop";
				interrupts = < 0x90 0x1 >;
				label = "SNOOP";
				status = "okay";
				port = < 0x80 >, < 0x81 >;
			};
			mbox: mbox {
				compatible = "aspeed,mbox";
				interrupts = < 0x36 0x1 >;
				label = "MBOX";
				status = "disabled";
			};
			pcc: pcc {
				compatible = "aspeed,pcc";
				interrupts = < 0x91 0x1 >;
				label = "PCC";
				status = "disabled";
			};
		};
		fmc: spi@7e620000 {
			compatible = "aspeed,spi-controller";
			reg = < 0x7e620000 0xc4 >, < 0x80000000 0x10000000 >;
			reg-names = "ctrl_reg", "spi_mmap";
			interrupts = < 0x27 0x1 >;
			clocks = < &sysclk 0x41 >;
			pinctrl-0 = < &pinctrl_fmc_quad >;
			num-cs = < 0x2 >;
			ast-platform = < 0x406 >;
			ctrl-type = "bspi";
			label = "FMC";
			#address-cells = < 0x1 >;
			#size-cells = < 0x0 >;
			spi-ctrl-caps-mask = < 0xe0e0c >;
			status = "okay";
			fmc_cs0: flash@0 {
				compatible = "jedec,spi-nor";
				reg = < 0x0 >;
				spi-max-buswidth = < 0x4 >;
				spi-max-frequency = < 0x2faf080 >;
				jedec-id;
				label = "fmc_cs0";
				write-block-size = < 0x1000 >;
				status = "okay";
				partitions {
					compatible = "fixed-partitions";
					#address-cells = < 0x1 >;
					#size-cells = < 0x1 >;
					boot_partition: partition@0 {
						label = "image-0";
						reg = < 0x0 0x100000 >;
					};
					dfu_partition: partition@1 {
						label = "image-1";
						reg = < 0x0 0x100000 >;
					};
				};
			};
			fmc_cs1: flash@1 {
				compatible = "jedec,spi-nor";
				reg = < 0x1 >;
				spi-max-buswidth = < 0x4 >;
				spi-max-frequency = < 0x2faf080 >;
				jedec-id;
				label = "fmc_cs1";
				status = "disabled";
			};
		};
		spi1: spi@7e630000 {
			compatible = "aspeed,spi-controller";
			reg = < 0x7e630000 0xc4 >, < 0x90000000 0x10000000 >;
			reg-names = "ctrl_reg", "spi_mmap";
			interrupts = < 0x41 0x1 >;
			clocks = < &sysclk 0x41 >;
			pinctrl-0 = < &pinctrl_spi1_quad >;
			num-cs = < 0x2 >;
			ast-platform = < 0x406 >;
			ctrl-type = "hspi";
			label = "SPI1";
			#address-cells = < 0x1 >;
			#size-cells = < 0x0 >;
			spi-ctrl-caps-mask = < 0xe0e0c >;
			status = "okay";
			spi1_cs0: flash@0 {
				compatible = "jedec,spi-nor";
				reg = < 0x0 >;
				spi-max-buswidth = < 0x4 >;
				spi-max-frequency = < 0x2faf080 >;
				jedec-id;
				label = "spi1_cs0";
				status = "okay";
				re-init-support;
			};
			spi1_cs1: flash@1 {
				compatible = "jedec,spi-nor";
				reg = < 0x1 >;
				spi-max-buswidth = < 0x4 >;
				spi-max-frequency = < 0x2faf080 >;
				jedec-id;
				label = "spi1_cs1";
				status = "disabled";
				re-init-support;
			};
		};
		spi2: spi@7e640000 {
			compatible = "aspeed,spi-controller";
			reg = < 0x7e640000 0xc4 >, < 0xb0000000 0x10000000 >;
			reg-names = "ctrl_reg", "spi_mmap";
			interrupts = < 0x42 0x1 >;
			clocks = < &sysclk 0x41 >;
			pinctrl-0 = < &pinctrl_spi2_default &pinctrl_spi2_cs1 &pinctrl_spi2_quad >;
			num-cs = < 0x2 >;
			ast-platform = < 0x406 >;
			ctrl-type = "nspi";
			label = "SPI2";
			#address-cells = < 0x1 >;
			#size-cells = < 0x0 >;
			spi-ctrl-caps-mask = < 0xe0e0c >;
			status = "disabled";
			spi2_cs0: flash@0 {
				compatible = "jedec,spi-nor";
				reg = < 0x0 >;
				spi-max-buswidth = < 0x4 >;
				spi-max-frequency = < 0x2faf080 >;
				jedec-id;
				label = "spi2_cs0";
				status = "disabled";
				re-init-support;
			};
			spi2_cs1: flash@1 {
				compatible = "jedec,spi-nor";
				reg = < 0x1 >;
				spi-max-buswidth = < 0x4 >;
				spi-max-frequency = < 0x2faf080 >;
				jedec-id;
				label = "spi2_cs1";
				status = "disabled";
				re-init-support;
			};
			spi2_cs2: flash@2 {
				compatible = "jedec,spi-nor";
				reg = < 0x2 >;
				spi-max-buswidth = < 0x4 >;
				spi-max-frequency = < 0x2faf080 >;
				jedec-id;
				label = "spi2_cs2";
				status = "disabled";
			};
			spi2_cs3: flash@3 {
				compatible = "jedec,spi-nor";
				reg = < 0x3 >;
				spi-max-buswidth = < 0x4 >;
				spi-max-frequency = < 0x2faf080 >;
				jedec-id;
				label = "spi2_cs3";
				status = "disabled";
			};
		};
		spim0: spi_monitor_common@7e791000 {
			compatible = "aspeed,spi-monitor-controller";
			reg = < 0x7e791000 0x4000 >;
			aspeed,scu = < &syscon >;
			#address-cells = < 0x1 >;
			#size-cells = < 0x0 >;
			label = "spi_m_common";
			status = "disabled";
			spim1: spi_monitor@1 {
				interrupts = < 0x57 0x1 >;
				reg = < 0x1 >;
				label = "spi_m1";
				allow-cmds;
				read-forbidden-regions;
				write-forbidden-regions;
				status = "disabled";
			};
			spim2: spi_monitor@2 {
				interrupts = < 0x58 0x1 >;
				reg = < 0x2 >;
				label = "spi_m2";
				allow-cmds;
				read-forbidden-regions;
				write-forbidden-regions;
				status = "disabled";
			};
			spim3: spi_monitor@3 {
				interrupts = < 0x59 0x1 >;
				reg = < 0x3 >;
				label = "spi_m3";
				allow-cmds;
				read-forbidden-regions;
				write-forbidden-regions;
				status = "disabled";
			};
			spim4: spi_monitor@4 {
				interrupts = < 0x5a 0x1 >;
				reg = < 0x4 >;
				label = "spi_m4";
				allow-cmds;
				read-forbidden-regions;
				write-forbidden-regions;
				status = "disabled";
			};
		};
		wdt0: wdt_common@7e785000 {
			compatible = "aspeed,ast-watchdog";
			interrupts = < 0x18 0x1 >;
			reg = < 0x7e785000 0x200 >;
			#address-cells = < 0x1 >;
			#size-cells = < 0x0 >;
			label = "wdt0";
			status = "okay";
			wdt1: wdt@1 {
				reg = < 0x1 >;
				aspeed,scu = < &syscon >;
				reset-mask = < 0x30f1ff1 0x3fffff1 >;
				label = "wdt1";
				status = "okay";
			};
			wdt2: wdt@2 {
				reg = < 0x2 >;
				aspeed,scu = < &syscon >;
				reset-mask = < 0x30f1ff1 0x3fffff1 >;
				label = "wdt2";
				status = "okay";
			};
			wdt3: wdt@3 {
				reg = < 0x3 >;
				aspeed,scu = < &syscon >;
				reset-mask = < 0x30f1ff1 0x3fffff1 >;
				label = "wdt3";
				status = "okay";
			};
			wdt4: wdt@4 {
				reg = < 0x4 >;
				aspeed,scu = < &syscon >;
				reset-mask = < 0x30f1ff1 0x3fffff1 >;
				label = "wdt4";
				status = "okay";
			};
		};
		i3c: bus@7e7a0000 {
			compatible = "simple-bus";
			#address-cells = < 0x1 >;
			#size-cells = < 0x1 >;
			ranges = < 0x0 0x7e7a0000 0x8000 >;
			i3c_gr: i3c-global-regs@0 {
				compatible = "aspeed,i3c-global";
				#address-cells = < 0x1 >;
				#size-cells = < 0x0 >;
				reg = < 0x0 0x100 >;
				resets = < &sysrst 0x505407 >;
				ni3cs = < 0x4 >;
				status = "okay";
				pull-up-resistor-ohm = < 0x7d0 >, < 0x7d0 >, < 0x7d0 >, < 0x7d0 >, < 0x7d0 >, < 0x7d0 >;
			};
			i3c0: i3c0@2000 {
				compatible = "aspeed,i3c";
				#address-cells = < 0x1 >;
				#size-cells = < 0x0 >;
				reg = < 0x2000 0x1000 >;
				interrupts = < 0x66 0x0 >;
				resets = < &sysrst 0x505408 >;
				clocks = < &sysclk 0x28 >;
				i2c-scl-hz = < 0xf4240 >;
				i3c-scl-hz = < 0xbebc20 >;
				i3c-pp-scl-hi-period-ns = < 0x28 >;
				i3c-pp-scl-lo-period-ns = < 0x28 >;
				i3c-od-scl-hi-period-ns = < 0x17c >;
				i3c-od-scl-lo-period-ns = < 0x26c >;
				sda-tx-hold-ns = < 0xa >;
				instance-id = < 0x0 >;
				pinctrl-0 = < &pinctrl_hvi3c0_default >;
				status = "disabled";
				label = "I3C_0";
			};
			i3c1: i3c1@3000 {
				compatible = "aspeed,i3c";
				#address-cells = < 0x1 >;
				#size-cells = < 0x0 >;
				reg = < 0x3000 0x1000 >;
				interrupts = < 0x67 0x0 >;
				resets = < &sysrst 0x505409 >;
				clocks = < &sysclk 0x29 >;
				i2c-scl-hz = < 0xf4240 >;
				i3c-scl-hz = < 0xbebc20 >;
				i3c-pp-scl-hi-period-ns = < 0x28 >;
				i3c-pp-scl-lo-period-ns = < 0x28 >;
				i3c-od-scl-hi-period-ns = < 0x17c >;
				i3c-od-scl-lo-period-ns = < 0x26c >;
				sda-tx-hold-ns = < 0xa >;
				instance-id = < 0x1 >;
				pinctrl-0 = < &pinctrl_hvi3c1_default >;
				status = "disabled";
				label = "I3C_1";
			};
			i3c2: i3c2@4000 {
				compatible = "aspeed,i3c";
				#address-cells = < 0x1 >;
				#size-cells = < 0x0 >;
				reg = < 0x4000 0x1000 >;
				interrupts = < 0x68 0x0 >;
				resets = < &sysrst 0x50540a >;
				clocks = < &sysclk 0x2a >;
				i2c-scl-hz = < 0xf4240 >;
				i3c-scl-hz = < 0xbebc20 >;
				i3c-pp-scl-hi-period-ns = < 0x28 >;
				i3c-pp-scl-lo-period-ns = < 0x28 >;
				i3c-od-scl-hi-period-ns = < 0x17c >;
				i3c-od-scl-lo-period-ns = < 0x26c >;
				sda-tx-hold-ns = < 0xa >;
				instance-id = < 0x2 >;
				status = "disabled";
				label = "I3C_2";
			};
			i3c3: i3c3@5000 {
				compatible = "aspeed,i3c";
				#address-cells = < 0x1 >;
				#size-cells = < 0x0 >;
				reg = < 0x5000 0x1000 >;
				interrupts = < 0x69 0x0 >;
				resets = < &sysrst 0x50540b >;
				clocks = < &sysclk 0x2b >;
				i2c-scl-hz = < 0xf4240 >;
				i3c-scl-hz = < 0x4c4b40 >;
				i3c-pp-scl-hi-period-ns = < 0x64 >;
				i3c-pp-scl-lo-period-ns = < 0x64 >;
				i3c-od-scl-hi-period-ns = < 0x17c >;
				i3c-od-scl-lo-period-ns = < 0x26c >;
				sda-tx-hold-ns = < 0xa >;
				instance-id = < 0x3 >;
				status = "okay";
				label = "I3C_3";
				assigned-address = < 0x11 >;
				pinctrl-0 = < &pinctrl_i3c3_default >;
			};
		};
		hace: hace@7e6d0000 {
			compatible = "aspeed,hace";
			#address-cells = < 0x1 >;
			#size-cells = < 0x1 >;
			reg = < 0x7e6d0000 0x200 0x7e6f2800 0x10 >;
			clocks = < &sysclk 0xd >;
			resets = < &sysrst 0x404404 >;
		};
		rng: hwrng@7e6e2530 {
			compatible = "aspeed,hwrng";
			reg = < 0x7e6e2530 0x10 >;
			label = "RNG";
		};
		sbc: sbc@7e6f2000 {
			reg = < 0x7e6f2000 0x100 0x79000000 0x2400 >;
			rsa: rsa {
				compatible = "aspeed,rsa";
				clocks = < &sysclk 0x26 >;
				label = "RSA";
			};
			ecdsa: ecdsa {
				compatible = "aspeed,ecdsa";
				label = "ECDSA";
			};
			otp: otp {
				compatible = "aspeed,otp";
				otpcfg;
				otpstrap;
			};
		};
	};
	cpus {
		#address-cells = < 0x1 >;
		#size-cells = < 0x0 >;
		cpu@0 {
			device_type = "cpu";
			compatible = "arm,cortex-m4f";
			reg = < 0x0 >;
		};
	};
	sram0: memory@0 {
		compatible = "mmio-sram";
		reg = < 0x0 0x70000 >, < 0x70000 0x50000 >;
	};
};
